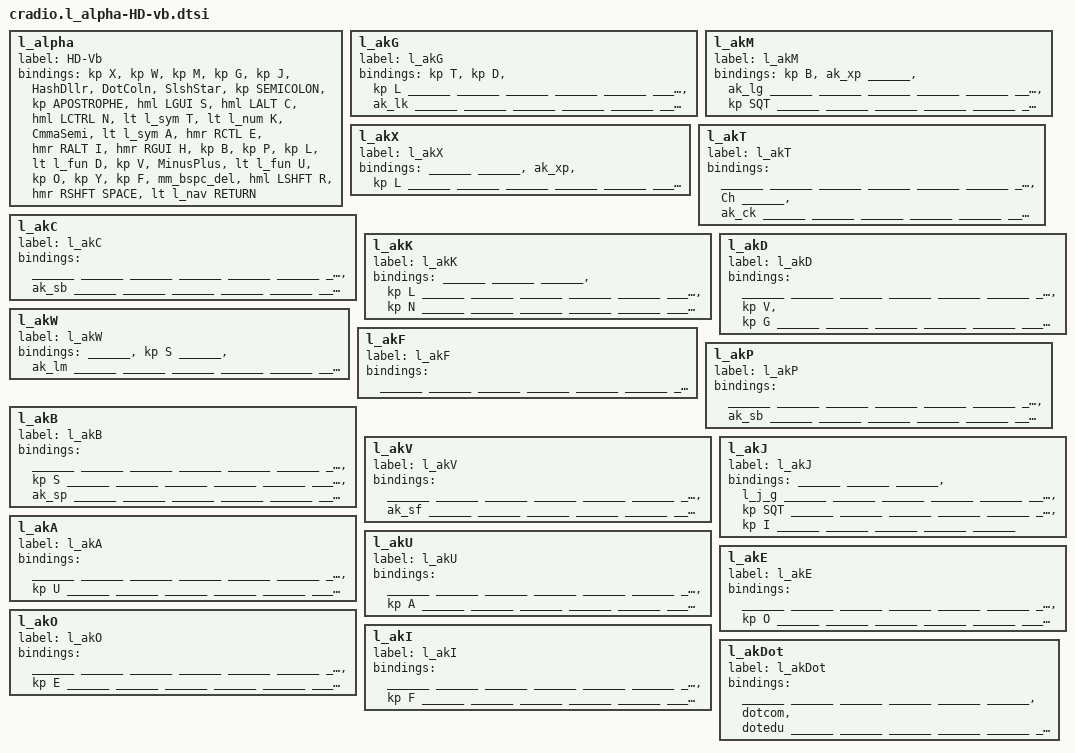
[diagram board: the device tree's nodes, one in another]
#define ______  &trans

/*  Base (alpha) Layer  Hands Down Vibranium-Vb
    Building for a 36/42 key board
     ╭─────────────────────╮ ╭──────────────────────╮
ESC  │  X   W   M   G   J  │ │  #$  .:  /*   ;  '   │ BSP
TAB  │  S   C   N   T   K  | |  ,;   A   E   I   H  │ Tg(Num)
LSFT │  B   P   L   D   V  │ │  -+   U   O   Y   F  │ RSFT
     ╰──────╮  App BSP  R  │ │  SPC RET TAB  ╭──────╯
            ╰──────────────╯ ╰───────────────╯
*/


                l_alpha {
                        label = "HD-Vb";
                        bindings = <

&kp X  &kp W   &kp M   &kp G   &kp  J           &HashDllr   &DotColn    &SlshStar   &kp SEMICOLON    &kp APOSTROPHE
&hml LGUI S &hml LALT C   &hml LCTRL N  &lt l_sym T &lt l_num K    &CmmaSemi   &lt l_sym A &hmr RCTL E  &hmr RALT I  &hmr RGUI H
&kp B &kp P   &kp L   &lt l_fun  D  &kp V              &MinusPlus  &lt l_fun U       &kp O       &kp Y   &kp F

                        &mm_bspc_del &hml LSHFT R      &hmr RSHFT SPACE &lt l_nav RETURN
                        >;
                };

                   l_akG {
                            label = "l_akG";
                            bindings = <
&kp T   &kp D   &kp L   ______  ______      ______  ______  ______  ______  ______
______  ______  ______  ______  &ak_lk      ______  ______  ______  ______  ______
______  ______  ______  ______  ______      ______  ______  ______  ______  ______
                        ______  ______      ______  ______
                            >;
                   };
                   l_akM {
                            label = "l_akM";
                            bindings = <
&kp B   &ak_xp  ______  &ak_lg  ______      ______  ______  ______  ______  ______  ______
______  ______  ______  ______  ______      ______  ______  ______  ______  &kp SQT ______
______  ______  ______  ______  ______      ______  ______  ______  ______  ______  ______
                        ______  ______      ______  ______
                            >;
                   };
                   l_akX {
                            label = "l_akX";
                            bindings = <
______  ______  &ak_xp  &kp L   ______      ______  ______  ______  ______  ______
______  ______  ______  ______  ______      ______  ______  ______  ______  ______
______  ______  ______  ______  ______      ______  ______  ______  ______  ______
                        ______  ______      ______  ______
                            >;
                   };
                   l_akT {
                            label = "l_akT";
                            bindings = <
______  ______  ______  ______  ______      ______  ______  ______  ______  ______
______  ______  &Ch     ______  &ak_ck      ______  ______  ______  ______  ______
______  ______  ______  ______  ______      ______  ______  ______  ______  ______
                        ______  ______      ______  ______
                            >;
                   };
                   l_akC {
                            label = "l_akC";
                            bindings = <
______  ______  ______  ______  ______      ______  ______  ______  ______  ______
______  ______  ______  ______  ______      ______  ______  ______  ______  ______
______  &ak_sb  ______  ______  ______      ______  ______  ______  ______  ______
                        ______  ______      ______  ______
                            >;
                   };
                   l_akK {
                            label = "l_akK";
                            bindings = <
______  ______  ______  &kp L   ______      ______  ______  ______  ______  ______
______  ______  ______  &kp N   ______      ______  ______  ______  ______  ______
______  ______  ______  ______  ______      ______  ______  ______  ______  ______
                        ______  ______      ______  ______
                            >;
                   };
                   l_akD {
                            label = "l_akD";
                            bindings = <
______  ______  ______  ______  ______      ______  ______  ______  ______  ______
______  ______  ______  ______  ______      ______  ______  ______  ______  ______
______  &kp V   &kp G   ______  ______      ______  ______  ______  ______  ______
                        ______  ______      ______  ______
                             >;
                   };
                   l_akW {
                            label = "l_akW";
                            bindings = <
______  &kp S   ______  &ak_lm  ______      ______  ______  ______  ______  ______
______  ______  ______  ______  ______      ______  ______  ______  ______  ______
______  ______  ______  ______  ______      ______  ______  ______  ______  ______
                        ______  ______      ______  ______
                            >;
                   };
                   l_akF {
                            label = "l_akF";
                            bindings = <
______  ______  ______  ______  ______      ______  ______  ______  ______  ______
______  ______  ______  ______  ______      ______  ______  ______  ______  ______
______  ______  ______  ______  ______      ______  ______  ______  ______  ______
                        ______  ______      ______  ______
                            >;
                   };
                   l_akP {
                            label = "l_akP";
                            bindings = <
______  ______  ______  ______  ______      ______  ______  ______  ______  ______
______  ______  ______  ______  ______      ______  ______  ______  ______  ______
______  &ak_sb  ______  ______  ______      ______  ______  ______  ______  ______
                        ______  ______      ______  ______
                            >;
                   };
                   l_akB {
                            label = "l_akB";
                            bindings = <
______  ______  ______  ______  ______      ______  ______  ______  ______  ______
______  ______  &kp S   ______  ______      ______  ______  ______  ______  ______
______  ______  &ak_sp  ______  ______      ______  ______  ______  ______  ______
                        ______  ______      ______  ______
                            >;
                   };
                   l_akV {
                            label = "l_akV";
                            bindings = <
______  ______  ______  ______  ______      ______  ______  ______  ______  ______
______  ______  ______  ______  ______      ______  ______  ______  ______  ______
______  ______  &ak_sf  ______  ______      ______  ______  ______  ______  ______
                        ______  ______      ______  ______
                            >;
                   };
                   l_akJ {
                            label = "l_akJ";
                            bindings = <
______  ______  ______  &l_j_g  ______      ______  ______  ______  ______  ______
______  ______  ______  ______  ______      ______  ______  ______  &kp SQT ______
______  ______  ______  ______  ______      ______  ______  ______  &kp I   ______
                        ______  ______      ______  ______
                            >;
                   };

                   l_akA {
                            label = "l_akA";
                            bindings = <
______  ______  ______  ______  ______      ______  ______  ______  ______  ______
______  ______  ______  ______  ______      ______  ______  ______  &kp U   ______
______  ______  ______  ______  ______      ______  ______  ______  ______  ______
                        ______  ______      ______  ______
                            >;
                   };
                   l_akU {
                            label = "l_akU";
                            bindings = <
______  ______  ______  ______  ______      ______  ______  ______  ______  ______
______  ______  ______  ______  ______      ______  ______  ______  &kp A   ______
______  ______  ______  ______  ______      ______  ______  ______  ______  ______
                        ______  ______      ______  ______
                            >;
                   };
                   l_akE {
                            label = "l_akE";
                            bindings = <
______  ______  ______  ______  ______      ______  ______  ______  ______  ______
______  ______  ______  ______  ______      ______  ______  ______  &kp O   ______
______  ______  ______  ______  ______      ______  ______  ______  ______  ______
                        ______  ______      ______  ______
                            >;
                   };
                   l_akO {
                            label = "l_akO";
                            bindings = <
______  ______  ______  ______  ______      ______  ______  ______  ______  ______
______  ______  ______  ______  ______      ______  ______  ______  &kp E   ______
______  ______  ______  ______  ______      ______  ______  ______  ______  ______
                        ______  ______      ______  ______
                            >;
                   };
                   l_akI {
                            label = "l_akI";
                            bindings = <
______  ______  ______  ______  ______      ______  ______  ______  ______  ______
______  ______  ______  ______  ______      ______  ______  ______  &kp F   ______
______  ______  ______  ______  ______      ______  ______  ______  ______  ______
                        ______  ______      ______  ______
                            >;
                   };

                   l_akDot {
                            label = "l_akDot";
                            bindings = <
______  ______  ______  ______  ______      ______  &dotcom &dotedu ______  ______
______  ______  ______  ______  ______      ______  ______  ______  ______  ______
______  ______  ______  ______  ______      ______  ______  ______  ______  ______
                        ______  ______      ______  ______
                            >;
                   };
